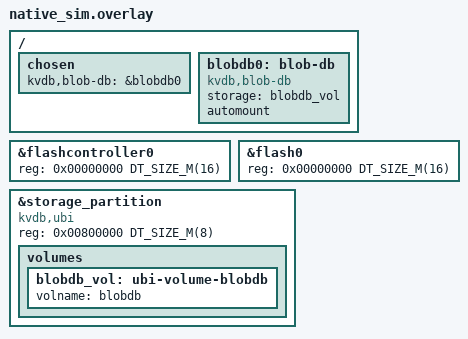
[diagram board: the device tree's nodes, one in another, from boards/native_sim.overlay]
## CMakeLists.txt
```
#-------------------------------------------------------------------------------
# Zephyr Key-Value DB — blob_db demo application
#
# Copyright (c) 2021 Nordic Semiconductor ASA
# SPDX-License-Identifier: Apache-2.0

cmake_minimum_required(VERSION 3.13.1)
find_package(Zephyr REQUIRED HINTS $ENV{ZEPHYR_BASE})

project(app LANGUAGES C)

# The repository is a Zephyr module (see zephyr/module.yml): its top-level
# CMakeLists already exports include/ and adds lib/, and the blob_db library
# is built and auto-linked when CONFIG_BLOB_DB=y. Re-adding lib/ here would
# create a duplicate `blob_db` target, so the app only adds its own sources.
target_sources(app PRIVATE src/main.c)

# The code below locates the git index file for this repository and adds it as a dependency for
# the application VERSION file so that if the repo has a new commit added, even if no files in
# the build have changed, the application version file will be regenerated with the new git commit
find_package(Git QUIET)
if(GIT_FOUND)
  execute_process(
    COMMAND ${GIT_EXECUTABLE} rev-parse --absolute-git-dir
    WORKING_DIRECTORY .
    OUTPUT_VARIABLE application_git_dir
    OUTPUT_STRIP_TRAILING_WHITESPACE
    ERROR_STRIP_TRAILING_WHITESPACE
    ERROR_VARIABLE stderr
    RESULT_VARIABLE return_code
  )
  # If there is an error e.g. it is not a git repo, we just silently ignore it and continue
  # without a dependency, this will be the case with freestanding applications.
  if(NOT return_code)
    if(NOT "${stderr}" STREQUAL "")
      message(WARNING "Application build version git rev-parse warned: ${stderr}")
    endif()

    set_property(TARGET app_version_h PROPERTY APP_VERSION_DEPENDS ${application_git_dir}/index)
  endif()
endif()
```

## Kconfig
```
# Copyright (c) 2021 Nordic Semiconductor ASA
# SPDX-License-Identifier: Apache-2.0
#
# This file is the application Kconfig entry point. All application Kconfig
# options can be defined here or included via other application Kconfig files.
# You can browse these options using the west targets menuconfig (terminal) or
# guiconfig (GUI).

menu "Zephyr"
source "Kconfig.zephyr"
endmenu

# The in-repo libraries' Kconfig (CONFIG_BLOB_DB and friends) is contributed
# by the repository's module Kconfig entry point (zephyr/module.yml -> Kconfig
# -> rsource lib/Kconfig), so it must not be sourced again here.

module = APP
module-str = APP
source "subsys/logging/Kconfig.template.log_config"
```

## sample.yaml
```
# This file is provided so that the application can be compiled using Twister,
# the Zephyr testing tool. In this file, multiple combinations can be specified,
# so that you can easily test all of them locally or in CI.
sample:
  description: blob_db demo — a boot counter persisted at the root id
  name: blob-db-demo
common:
  build_only: true
  integration_platforms:
    - custom_plank
    - nucleo_f302r8
tests:
  app.default: {}
  app.debug:
    extra_overlay_confs:
      - debug.conf
```

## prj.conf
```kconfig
# Copyright (c) 2021 Nordic Semiconductor ASA
# SPDX-License-Identifier: Apache-2.0
#
# This file contains selected Kconfig options for the application.

CONFIG_LOG=y
CONFIG_APP_LOG_LEVEL_DBG=y

# blob_db (stable-id blob store) needs no line here: the kvdb,blob-db node in
# boards/<board>.overlay switches it on, says where the store lives and
# mounts it at boot ("automount").
#
# The storage backend follows the node's "storage" property: a UBI volume
# (zephyr-ubi) for wear-leveling, bad-block handling and authenticated
# metadata, or a plain partition for the raw flash_area backend — faster, but
# no wear-leveling and no bad-block handling. CONFIG_UBI and PSA Crypto come
# with UBI, and its heap is sized from the partition
# (CONFIG_BLOB_DB_UBI_HEAP_SIZE). The overlays here use a UBI volume; to run
# the same partition raw instead, override the backend:
#   west build -b native_sim app -- -DCONFIG_BLOB_DB_BACKEND_FLASH_AREA=y
# The two on-flash layouts are not interchangeable; erase the partition when
# switching an existing device between them.

# blob_db stack-allocates a 4 KB bucket buffer per op, and during
# compaction allocates a second 4 KB scratch buffer nested under it.
# 32 KB gives plenty of headroom for native_sim's frame overhead.
CONFIG_MAIN_STACK_SIZE=32768
```

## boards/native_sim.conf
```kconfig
# blob_db_erase_all() invalidates bucket headers by programming 0x00 over
# already-programmed magic bytes (1->0 only — legal on real NOR without an
# erase). The flash simulator rejects program-over-non-erased by default;
# allow it so the demo's every-Nth-boot erase_all works on native_sim.
CONFIG_FLASH_SIMULATOR_DOUBLE_WRITES=y

# UBI static PEB pool: native_sim's 8 MB partition in the simulator's default
# 4 KB erase blocks is 2048 PEBs, less the 2 reserved for headers.
CONFIG_UBI_MAX_NR_OF_DATA_PEBS=2046
```

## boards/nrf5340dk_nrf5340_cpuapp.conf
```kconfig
# Board-specific Kconfig for nRF5340-DK cpuapp: the storage_partition sits
# on the on-board MX25R64 QSPI NOR (see nrf5340dk_nrf5340_cpuapp.overlay),
# whose sectors are 64 KB. Grow blob_db's sector buffer to fit.
CONFIG_BLOB_DB_SECTOR_BUF_SIZE=65536

# zephyr-ubi's heap: 8 B per erase block (128 of 64 KB here, so 1 KB) plus a
# handle and scratch buffer at attach and a second pair during a format. The
# default assumes 4 KB blocks and would reserve 20 KB.
CONFIG_BLOB_DB_UBI_HEAP_SIZE=6144
```

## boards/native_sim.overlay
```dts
/*
 * Resize native_sim's simulated flash to 16 MB and carve out an 8 MB
 * storage_partition for kv_db. Leaves the default mcuboot / slot partitions
 * in the first 1 MB intact so existing tooling expectations still hold.
 *
 * The partition is a UBI device holding one volume, and blob_db lives on
 * that volume (dts/bindings/mtd/kvdb,ubi.yaml, storage/kvdb,blob-db.yaml).
 * "automount" mounts the store before main() runs, so main() calls no init
 * function at all.
 *
 * See doc/layers/l1_blob_db.md §1 "Capacity".
 */

&flashcontroller0 {
	reg = <0x00000000 DT_SIZE_M(16)>;
};

&flash0 {
	reg = <0x00000000 DT_SIZE_M(16)>;
};

&storage_partition {
	/* Keep "zephyr,mapped-partition": it is what makes the node a partition
	 * on native_sim (its flash_map entry and partition id).
	 */
	compatible = "kvdb,ubi", "zephyr,mapped-partition";
	reg = <0x00800000 DT_SIZE_M(8)>;

	volumes {
		blobdb_vol: ubi-volume-blobdb {
			volname = "blobdb";
		};
	};
};

/ {
	chosen {
		kvdb,blob-db = &blobdb0;
	};

	blobdb0: blob-db {
		compatible = "kvdb,blob-db";
		storage = <&blobdb_vol>;
		automount;
	};
};
```

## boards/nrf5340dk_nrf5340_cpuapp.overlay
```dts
/*
 * Move blob_db's storage_partition off the app-core internal NVMC (32 KB
 * at 0xf8000) and onto the on-board MX25R64 QSPI NOR (8 MB). Matches the
 * 8 MB partition the native_sim overlay carves out, so tests and device
 * exercise the same geometry.
 */

/delete-node/ &storage_partition;

&mx25r64 {
	partitions {
		compatible = "fixed-partitions";
		#address-cells = <1>;
		#size-cells = <1>;

		storage_partition: partition@0 {
			compatible = "kvdb,ubi";
			label = "storage";
			reg = <0x00000000 0x00800000>;

			volumes {
				blobdb_vol: ubi-volume-blobdb {
					volname = "blobdb";
				};
			};
		};
	};
};

/*
 * The blob_db store on the volume above, mounted before main() runs.
 */
/ {
	chosen {
		kvdb,blob-db = &blobdb0;
	};

	blobdb0: blob-db {
		compatible = "kvdb,blob-db";
		storage = <&blobdb_vol>;
		automount;
	};
};
```

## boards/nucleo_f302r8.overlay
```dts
/*
 * Copyright (c) 2021 Nordic Semiconductor ASA
 * SPDX-License-Identifier: Apache-2.0
 */

/* This devicetree overlay file will be automatically picked by the Zephyr
 * build system when building the sample for the nucleo_f302r8 board. It shows
 * how this application can be built on sample boards already provided by
 * Zephyr.
 */

/ {
	example_sensor: example-sensor {
		compatible = "zephyr,example-sensor";
		input-gpios = <&gpioc 13 (GPIO_PULL_UP | GPIO_ACTIVE_LOW)>;
	};

	blink_led: blink-led {
		compatible = "blink-gpio-led";
		led-gpios = <&gpiob 13 GPIO_ACTIVE_HIGH>;
		blink-period-ms = <1000>;
	};
};

&gpioc {
	status = "okay";
};
```

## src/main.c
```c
/*
 * Copyright (c) 2026
 * SPDX-License-Identifier: Apache-2.0
 *
 * blob_db demo — increments a boot counter persisted at BLOB_DB_ROOT_ID
 * across reboots, exercising the "root always exists" contract documented
 * in include/app/lib/blob_db.h (@blob_db_root).
 *
 * Every ERASE_EVERY_N boots the demo calls blob_db_erase_all() to show the
 * fast wipe: prior blobs vanish, root is re-bound with an empty payload,
 * next allocation restarts at 2, and the boot counter resets to 1.
 *
 * Nothing here brings the store up. The board's devicetree describes it (the
 * kvdb,blob-db node in boards/<board>.overlay) and marks it "automount", so
 * the blob_db device mounts it before main() runs; device_is_ready() reports
 * whether that worked. Without "automount" the first blob_db call below would
 * mount it instead.
 *
 * Run natively with a backing flash file to see the count persist:
 *   ./zephyr.exe --flash=/tmp/blob.bin
 */

#include <errno.h>

#include <zephyr/kernel.h>
#include <zephyr/logging/log.h>

#include <app/lib/blob_db.h>
#include <app/lib/blob_db_device.h>

#include <zephyr/app_version.h>

#ifdef CONFIG_ARCH_POSIX
#include "posix_board_if.h"   /* posix_exit() — end the sim run cleanly */
#endif

LOG_MODULE_REGISTER(main, CONFIG_APP_LOG_LEVEL);

#define ERASE_EVERY_N  5

int main(void)
{
	printk("Zephyr Key-Value DB %s\n", APP_VERSION_STRING);

	int rc;

	if (!device_is_ready(BLOB_DB_DEVICE)) {
		LOG_ERR("blob_db did not mount at boot");
		rc = -ENODEV;
		goto out;
	}

	uint32_t boot_count;
	size_t got;

	/* Root is guaranteed live once mounted; distinguish virgin from used
	 * by the payload size — format() leaves it empty. */
	rc = blob_db_get(BLOB_DB_ROOT_ID, &boot_count, sizeof(boot_count), &got);
	if (rc < 0) {
		LOG_ERR("get root failed: %d", rc);
		goto out;
	}

	if (got == 0) {
		boot_count = 1;
		LOG_INF("first boot on a fresh store — boot_count=1");
	} else if (got == sizeof(boot_count)) {
		boot_count++;
		LOG_INF("boot #%u", boot_count);
	} else {
		LOG_ERR("root blob has unexpected size %zu", got);
		goto out;
	}

	rc = blob_db_update(BLOB_DB_ROOT_ID, &boot_count, sizeof(boot_count));
	if (rc < 0) {
		LOG_ERR("update root failed: %d", rc);
		goto out;
	}

	LOG_INF("blobs in store: %zu", blob_db_count());

	if (boot_count % ERASE_EVERY_N == 0) {
		LOG_INF("boot_count reached %u — exercising blob_db_erase_all()",
			boot_count);
		rc = blob_db_erase_all();
		if (rc < 0) {
			LOG_ERR("erase_all failed: %d", rc);
			goto out;
		}
		LOG_INF("erase_all done; blobs in store now: %zu "
			"(next boot resets counter)", blob_db_count());
	}

out:
	blob_db_unmount();
#ifdef CONFIG_ARCH_POSIX
	posix_exit(rc == 0 ? 0 : 1);
#endif
	return 0;
}
```
